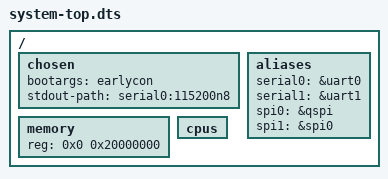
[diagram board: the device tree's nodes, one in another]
/*
 * CAUTION: This file is automatically generated by Xilinx.
 * Version: XSCT 2019.1
 * Today is: Thu Jan 16 19:11:36 2020
 */


/dts-v1/;
#include "zynq-7000.dtsi"
#include "pcw.dtsi"
/ {
	chosen {
		bootargs = "earlycon";
		stdout-path = "serial0:115200n8";
	};
	aliases {
		serial0 = &uart0;
		serial1 = &uart1;
		spi0 = &qspi;
		spi1 = &spi0;
	};
	memory {
		device_type = "memory";
		reg = <0x0 0x20000000>;
	};
	cpus {
	};
};
